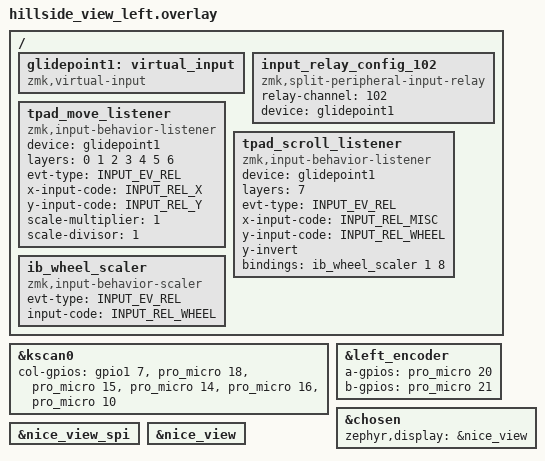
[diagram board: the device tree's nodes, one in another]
/*
 * Copyright (c) 2022 The ZMK Contributors
 *
 * SPDX-License-Identifier: MIT
 */

#include "hillside_view.dtsi"

&kscan0  {
    col-gpios
        = <&gpio1 7 GPIO_ACTIVE_HIGH>
        , <&pro_micro 18 GPIO_ACTIVE_HIGH>
        , <&pro_micro 15 GPIO_ACTIVE_HIGH>
        , <&pro_micro 14 GPIO_ACTIVE_HIGH>
        , <&pro_micro 16 GPIO_ACTIVE_HIGH>
        , <&pro_micro 10 GPIO_ACTIVE_HIGH>
        ;
};

&left_encoder {
    status = "okay";
  a-gpios = <&pro_micro 20 (GPIO_ACTIVE_HIGH | GPIO_PULL_UP)>;
  b-gpios = <&pro_micro 21 (GPIO_ACTIVE_HIGH | GPIO_PULL_UP)>;
};

&chosen {
  zephyr,display = &nice_view;
};

// nice view bus
&nice_view_spi {
  status = "okay";
};

&nice_view {
  status = "okay";
};

/ {
	/* define virtual input, will be resurrected for emitting input event */
	glidepoint1: virtual_input {
		compatible = "zmk,virtual-input";
	};

	/* for central side, define (relay-channel)-to-(virtual-input) mapping */
	input_relay_config_102 {
		compatible = "zmk,split-peripheral-input-relay";
		relay-channel = <102>;
		device = <&glidepoint1>;
	};

	/* Mouse movement config - default layer */
	tpad_move_listener {
		compatible = "zmk,input-behavior-listener";
		device = <&glidepoint1>;
		layers = <0 1 2 3 4 5 6>;  /* All layers except scroll layer */

		evt-type = <INPUT_EV_REL>;
		x-input-code = <INPUT_REL_X>;
		y-input-code = <INPUT_REL_Y>;

		/* Scale: reduce sensitivity (higher divisor = slower cursor) */
		scale-multiplier = <1>;
		scale-divisor = <1>;

		/* Optional: invert Y axis if needed */
		// y-invert;
	};

	/* Mouse scroll config - activated by layer or behavior */
	tpad_scroll_listener {
		compatible = "zmk,input-behavior-listener";
		device = <&glidepoint1>;
		layers = <7>;  /* Scroll layer (add SCROLL layer to keymap) */

		evt-type = <INPUT_EV_REL>;
		x-input-code = <INPUT_REL_MISC>;  /* Silence X for scroll */
		y-input-code = <INPUT_REL_WHEEL>;

		y-invert;  /* Natural scrolling */

		/* Smooth scrolling with accumulator */
		bindings = <&ib_wheel_scaler 1 8>;
	};

	/* Scroll scaler for smooth scrolling */
	ib_wheel_scaler: ib_wheel_scaler {
		compatible = "zmk,input-behavior-scaler";
		#binding-cells = <2>;
		evt-type = <INPUT_EV_REL>;
		input-code = <INPUT_REL_WHEEL>;
	};
};
